AUTOSAR XML (schema 00050)
package /SSM_Master/ComponentTypes
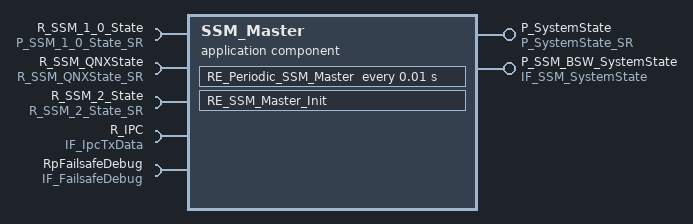
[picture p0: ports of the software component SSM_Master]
  application sw component type SSM_Master
    provide port P_SystemState: nonqueued-sender-com-spec{data-element=SystemState, init-value=fields=[SystemState:0, DegradedState:0]}, provided-interface=P_SystemState_SR
    4 x require port:
      R_SSM_1_0_State: nonqueued-receiver-com-spec{data-element=State_1_0, init-value=fields=[CoreStatus:0, LocalAppStatus:20 x 0]}, required-interface=P_SSM_1_0_State_SR
      R_SSM_QNXState: nonqueued-receiver-com-spec{data-element=State_QNX, init-value=fields=[CoreStatus:0, LocalAppStatus:20 x 0]}, required-interface=R_SSM_QNXState_SR
      R_SSM_2_State: required-interface=R_SSM_2_State_SR
        required-com-specs:
          data-element=State_2_0, init-value=fields=[CoreStatus:0, LocalAppStatus:20 x 0]
          data-element=State_2_1, filter=data-filter-type=ALWAYS, init-value=fields=[CoreStatus:0, LocalAppStatus:20 x 0]
      R_IPC: client-com-spec=IPC_Write_v, required-interface=IF_IpcTxData
    provide port P_SSM_BSW_SystemState: mode-switch-sender-com-spec{mode-group=Mode, queue-length=1}, provided-interface=IF_SSM_SystemState
    require port RpFailsafeDebug: nonqueued-receiver-com-spec{data-element=Debugflag, filter=data-filter-type=ALWAYS, init-value=0}, required-interface=IF_FailsafeDebug
    behavior SSM_Master_InternalBehavior: handle-termination-and-restart=NO-SUPPORT
      timing event TMT_RE_Periodic_SSM_Master: start-on-event=RE_Periodic_SSM_Master, period=0.01
      init event InitEvent: start-on-event=RE_SSM_Master_Init
      port-api-options:
        enable-take-address=false, error-handling=NO-TRANSFORMER-ERROR-HANDLING, indirect-api=false, port=P_SystemState
        enable-take-address=false, error-handling=NO-TRANSFORMER-ERROR-HANDLING, indirect-api=false, port=R_SSM_1_0_State
        enable-take-address=false, error-handling=NO-TRANSFORMER-ERROR-HANDLING, indirect-api=false, port=R_SSM_QNXState
        enable-take-address=false, error-handling=NO-TRANSFORMER-ERROR-HANDLING, indirect-api=false, port=R_SSM_2_State
      runnable RE_Periodic_SSM_Master  # Periodic Runnable of Satellite
        data-receive-point-by-arguments:
          5 x access:
            REC_R_SSM_QNXState_State_QNX: accessed-variable=R_SSM_QNXState.State_QNX
            REC_R_SSM_1_0_State_State_1_0: accessed-variable=R_SSM_1_0_State.State_1_0
            REC_R_SSM_2_State_State_2_0: accessed-variable=R_SSM_2_State.State_2_0
            REC_R_SSM_2_State_State_2_1: accessed-variable=R_SSM_2_State.State_2_1
            REC_RpFailsafeDebug_Debugflag: accessed-variable=RpFailsafeDebug.Debugflag
        data-send-points:
          access SEND_P_SystemState_SystemState: accessed-variable=P_SystemState.SystemState
        mode switch point SWITCH_PpSSM_BSW_SystemState_Mode: mode-group=P_SSM_BSW_SystemState.Mode
        sync call SC_R_IPC_IPC_Write_v: operation=R_IPC.IPC_Write_v
      runnable RE_SSM_Master_Init
  swc implementation SSM_Master_Implementation: programming-language=C, vendor-id=0, behavior=SSM_Master_InternalBehavior
    code-descriptors:
      code Default: artifact-descriptors=autosar-engineering-object=category=SWSRC
